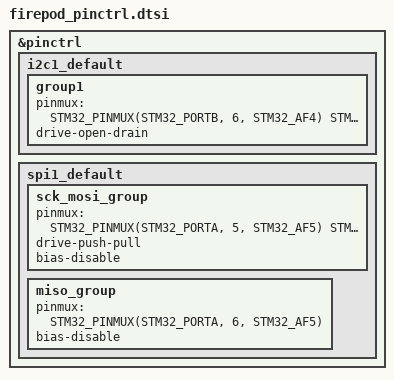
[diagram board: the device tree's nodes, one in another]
#include <zephyr/include/zephyr/dt-bindings/pinctrl/stm32-pinctrl-common.h>
#include <zephyr/include/zephyr/dt-bindings/pinctrl/stm32-pinctrl.h>

// STM32_PINMUX takes in (port, line, mode)
// pinctrl only needs to define the pins using alternate functions (alternate from GPIOs) or have different electrical behavior from the default GPIO
&pinctrl {
    i2c1_default: i2c1_default {
        group1 {
            pinmux = <
                STM32_PINMUX(STM32_PORTB, 6, STM32_AF4) /* SCL */
                STM32_PINMUX(STM32_PORTB, 7, STM32_AF4) /* SDA */
            >;
            drive-open-drain;
        }
    };
    // cs pin will go in the gpios
    spi1_default: spi1_default {
        sck_mosi_group {
            pinmux = <
                STM32_PINMUX(STM32_PORTA, 5, STM32_AF5) /* SCK  */
                STM32_PINMUX(STM32_PORTA, 7, STM32_AF5) /* MOSI */
            >;
            drive-push-pull;
            bias-disable;
        };

        miso_group {
            pinmux = <
                STM32_PINMUX(STM32_PORTA, 6, STM32_AF5) /* MISO */
            >;
            bias-disable; /* when would this be bias-pullup? */
        };
    }
};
